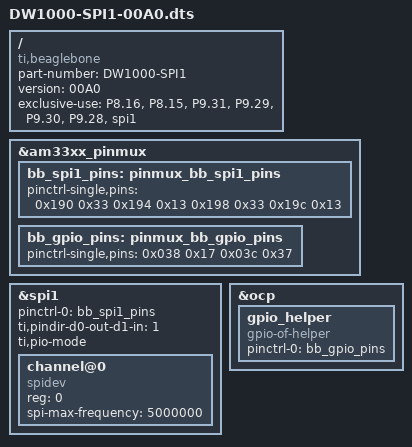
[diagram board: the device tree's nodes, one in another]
/*
* Copyright (C) 2016 Anh Luong <luong@eng.utah.edu>
*
* This program is free software; you can redistribute it and/or modify
* it under the terms of the GNU General Public License version 2 as
* published by the Free Software Foundation.
*/
/dts-v1/;
/plugin/;

/ {
	compatible = "ti,beaglebone", "ti,beaglebone-black", "ti,beaglebone-green";

	/* identification */
	part-number = "DW1000-SPI1";
	version = "00A0";

	/* state the resources this cape uses */
	exclusive-use =
		/* the pin header uses */
		"P8.16",	/* reset */
		"P8.15",	/* irq */
		"P9.31",	/* spi1_sclk */
		"P9.29",	/* spi1_d0 */
		"P9.30",	/* spi1_d1 */
		"P9.28",	/* spi1_cs0 */
		/* the hardware ip uses */
		"spi1";

	fragment@0 {
		target = <&am33xx_pinmux>;
		__overlay__ {
			/* default state has all gpios released and mode set to uart1 */
			bb_spi1_pins: pinmux_bb_spi1_pins {
				pinctrl-single,pins = <
					0x190 0x33	/* mcasp0_aclkx.spi1_sclk, OUTPUT_PULLUP 	| MODE3 */
					0x194 0x13	/* mcasp0_fsx.spi1_d0, OUTPUT_PULLUP 		| MODE3 */
					0x198 0x33	/* mcasp0_axr0.spi1_d1, INPUT_PULLUP 		| MODE3 */
					0x19c 0x13	/* mcasp0_ahclkr.spi1_cs0, OUTPUT_PULLUP 	| MODE3 */
				>;
			};
			bb_gpio_pins: pinmux_bb_gpio_pins {
				pinctrl-single,pins = <
					0x038 0x17  /* P8.16 RESET  	O_PULLUP 				| MODE7-GPIO1[14] */
          			0x03c 0x37  /* P8.15 IRQ    	I_PULLUP 				| MODE7-GPIO1[15] */
				>;
			};
		};
	};

	fragment@1 {
		target = <&spi1>;
		__overlay__ {
			#address-cells = <1>;
			#size-cells = <0>;

			status = "okay";
			pinctrl-names = "default";
			pinctrl-0 = <&bb_spi1_pins>;
			ti,pindir-d0-out-d1-in = <1>;
			ti,pio-mode; /* disable dma when used as an overlay, dma gets stuck at 160 bits */
			
			channel@0 {
				#address-cells = <1>;
				#size-cells = <0>;

				compatible = "spidev";

				reg = <0>;
				spi-max-frequency = <5000000>;
			};
		};
	};

	fragment@2 {
		target = <&ocp>;
		__overlay__ {
			gpio_helper {
				compatible = "gpio-of-helper";
				status = "okay";
				pinctrl-names = "default";
				pinctrl-0 = <&bb_gpio_pins>;
			};
		};
	};
};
